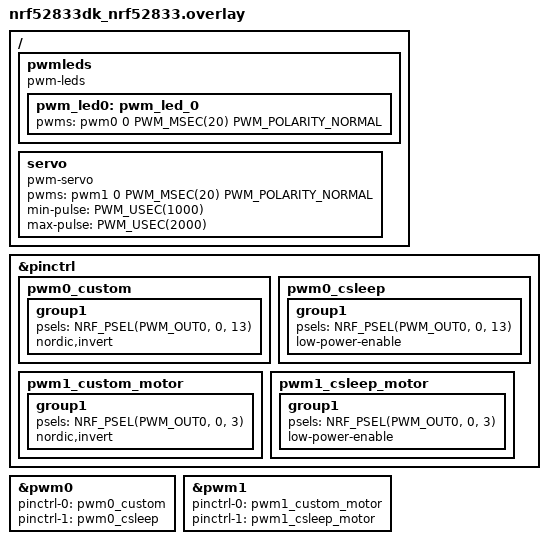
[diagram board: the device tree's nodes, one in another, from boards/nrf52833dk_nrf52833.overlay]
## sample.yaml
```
sample:
  description: nRF Connect SDK Intermediate Course by Nordic Developer Academy (https://academy.nordicsemi.com/)
  name: nRF Connect SDK Intermediate Course (Lesson 6 - Exercise 2 Solution)
```

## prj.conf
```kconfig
# Step 1 - Enable nrfx SAADC driver #
CONFIG_NRFX_SAADC=y
```

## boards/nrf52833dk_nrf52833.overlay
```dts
// To get started, press Ctrl+Space to bring up the completion menu and view the available nodes.

// You can also use the buttons in the sidebar to perform actions on nodes.
// Actions currently available include:

// * Enabling / disabling the node
// * Adding the bus to a bus
// * Removing the node
// * Connecting ADC channels

// For more help, browse the DeviceTree documentation at https://docs.zephyrproject.org/latest/guides/dts/index.html
// You can also visit the nRF DeviceTree extension documentation at https://nrfconnect.github.io/vscode-nrf-connect/devicetree/nrfdevicetree.html



/* STEP 1.4 - Define pwm0_custom and pwm0_sleep */
&pinctrl {
    pwm0_custom: pwm0_custom {
        group1 {
            psels = <NRF_PSEL(PWM_OUT0, 0, 13)>;
            nordic,invert;
        };
    };

    pwm0_csleep: pwm0_csleep {
        group1 {
            psels = <NRF_PSEL(PWM_OUT0, 0, 13)>;
            low-power-enable;
        };
    };
};
/* STEP 1.3 - Add the pwm0 instance */
&pwm0 {
    status = "okay";
    pinctrl-0 = <&pwm0_custom>;
    pinctrl-1 = <&pwm0_csleep>;
    pinctrl-names = "default", "sleep";
};

/{
/* STEP 1.2 -  Add a pwm_led instance and change the polarity */
    pwmleds {
        compatible = "pwm-leds";
        pwm_led0: pwm_led_0 {
            pwms = <&pwm0 0 PWM_MSEC(20) PWM_POLARITY_NORMAL>;
        };
    };
};



/* STEP 5.6 Select what GPIO pwm1 should drive */
&pinctrl {
    pwm1_custom_motor: pwm1_custom_motor {
        group1 {
            psels = <NRF_PSEL(PWM_OUT0, 0, 3)>;
            nordic,invert;
        };
    };

    pwm1_csleep_motor: pwm1_csleep_motor {
        group1 {
            psels = <NRF_PSEL(PWM_OUT0, 0, 3)>;
            low-power-enable;
        };
    };
};

&pwm1 {
    status = "okay";
    pinctrl-0 = <&pwm1_custom_motor>;
    pinctrl-1 = <&pwm1_csleep_motor>;
    pinctrl-names = "default", "sleep";
};

/* STEP 5.5 - Add the servo device  */
/ {
    servo: servo {
        compatible = "pwm-servo";
        pwms = <&pwm1 0 PWM_MSEC(20) PWM_POLARITY_NORMAL>;
        min-pulse = <PWM_USEC(1000)>;
        max-pulse = <PWM_USEC(2000)>;
    };
};
```

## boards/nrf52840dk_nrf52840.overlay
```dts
// To get started, press Ctrl+Space to bring up the completion menu and view the available nodes.

// You can also use the buttons in the sidebar to perform actions on nodes.
// Actions currently available include:

// * Enabling / disabling the node
// * Adding the bus to a bus
// * Removing the node
// * Connecting ADC channels

// For more help, browse the DeviceTree documentation at https://docs.zephyrproject.org/latest/guides/dts/index.html
// You can also visit the nRF DeviceTree extension documentation at https://nrfconnect.github.io/vscode-nrf-connect/devicetree/nrfdevicetree.html



/* STEP 1.4 - Define pwm0_custom and pwm0_sleep */
&pinctrl {
    pwm0_custom: pwm0_custom {
        group1 {
            psels = <NRF_PSEL(PWM_OUT0, 0, 10)>;
            nordic,invert;
        };
    };

    pwm0_csleep: pwm0_csleep {
        group1 {
            psels = <NRF_PSEL(PWM_OUT0, 0, 10)>;
            low-power-enable;
        };
    };
};
/* STEP 1.3 - Add the pwm0 instance */
&pwm0 {
    status = "okay";
    pinctrl-0 = <&pwm0_custom>;
    pinctrl-1 = <&pwm0_csleep>;
    pinctrl-names = "default", "sleep";
};

/{
/* STEP 1.2 -  Add a pwm_led instance and change the polarity */
    pwmleds {
        compatible = "pwm-leds";
        pwm_led0: pwm_led_0 {
            pwms = <&pwm0 0 PWM_MSEC(20) PWM_POLARITY_NORMAL>;
        };
    };
};


/* STEP 5.6 Select what GPIO pwm1 should drive */
&pinctrl {
    pwm1_custom_motor: pwm1_custom_motor {
        group1 {
            psels = <NRF_PSEL(PWM_OUT0, 0, 3)>;
            nordic,invert;
        };
    };

    pwm1_csleep_motor: pwm1_csleep_motor {
        group1 {
            psels = <NRF_PSEL(PWM_OUT0, 0, 3)>;
            low-power-enable;
        };
    };
};

&pwm1 {
    status = "okay";
    pinctrl-0 = <&pwm1_custom_motor>;
    pinctrl-1 = <&pwm1_csleep_motor>;
    pinctrl-names = "default", "sleep";
};

/* STEP 5.5 - Add the servo device  */
/ {
    servo: servo {
        compatible = "pwm-servo";
        pwms = <&pwm1 0 PWM_MSEC(20) PWM_POLARITY_NORMAL>;
        min-pulse = <PWM_USEC(1000)>;
        max-pulse = <PWM_USEC(2000)>;
    };
};
```

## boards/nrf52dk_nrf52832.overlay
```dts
// To get started, press Ctrl+Space to bring up the completion menu and view the available nodes.

// You can also use the buttons in the sidebar to perform actions on nodes.
// Actions currently available include:

// * Enabling / disabling the node
// * Adding the bus to a bus
// * Removing the node
// * Connecting ADC channels

// For more help, browse the DeviceTree documentation at https://docs.zephyrproject.org/latest/guides/dts/index.html
// You can also visit the nRF DeviceTree extension documentation at https://nrfconnect.github.io/vscode-nrf-connect/devicetree/nrfdevicetree.html



/* STEP 1.4 - Define pwm0_custom and pwm0_sleep */
&pinctrl {
    pwm0_custom: pwm0_custom {
        group1 {
            psels = <NRF_PSEL(PWM_OUT0, 0, 17)>;
            nordic,invert;
        };
    };

    pwm0_csleep: pwm0_csleep {
        group1 {
            psels = <NRF_PSEL(PWM_OUT0, 0, 17)>;
            low-power-enable;
        };
    };
};
/* STEP 1.3 - Add the pwm0 instance */
&pwm0 {
    status = "okay";
    pinctrl-0 = <&pwm0_custom>;
    pinctrl-1 = <&pwm0_csleep>;
    pinctrl-names = "default", "sleep";
};

/{
/* STEP 1.2 -  Add a pwm_led instance and change the polarity */
    pwmleds {
        compatible = "pwm-leds";
        pwm_led0: pwm_led_0 {
            pwms = <&pwm0 0 PWM_MSEC(20) PWM_POLARITY_NORMAL>;
        };
    };
};



/* STEP 5.6 Select what GPIO pwm1 should drive */
&pinctrl {
    pwm1_custom_motor: pwm1_custom_motor {
        group1 {
            psels = <NRF_PSEL(PWM_OUT0, 0, 3)>;
            nordic,invert;
        };
    };

    pwm1_csleep_motor: pwm1_csleep_motor {
        group1 {
            psels = <NRF_PSEL(PWM_OUT0, 0, 3)>;
            low-power-enable;
        };
    };
};

&pwm1 {
    status = "okay";
    pinctrl-0 = <&pwm1_custom_motor>;
    pinctrl-1 = <&pwm1_csleep_motor>;
    pinctrl-names = "default", "sleep";
};

/* STEP 5.5 - Add the servo device  */
/ {
    servo: servo {
        compatible = "pwm-servo";
        pwms = <&pwm1 0 PWM_MSEC(20) PWM_POLARITY_NORMAL>;
        min-pulse = <PWM_USEC(1000)>;
        max-pulse = <PWM_USEC(2000)>;
    };
};
```

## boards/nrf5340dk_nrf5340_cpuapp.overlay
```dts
// To get started, press Ctrl+Space to bring up the completion menu and view the available nodes.

// You can also use the buttons in the sidebar to perform actions on nodes.
// Actions currently available include:

// * Enabling / disabling the node
// * Adding the bus to a bus
// * Removing the node
// * Connecting ADC channels

// For more help, browse the DeviceTree documentation at https://docs.zephyrproject.org/latest/guides/dts/index.html
// You can also visit the nRF DeviceTree extension documentation at https://nrfconnect.github.io/vscode-nrf-connect/devicetree/nrfdevicetree.html




/* Step 1.4 - Define pwm0_custom and pwm0_sleep */
&pinctrl {
    pwm0_custom: pwm0_custom {
        group1 {
            psels = <NRF_PSEL(PWM_OUT0, 0, 3)>;
            nordic,invert;
        };
    };

    pwm0_csleep: pwm0_csleep {
        group1 {
            psels = <NRF_PSEL(PWM_OUT0, 0, 3)>;
            low-power-enable;
        };
    };
};
/* Step 1.3 - Add the pwm0 instance */
&pwm0 {
    status = "okay";
    pinctrl-0 = <&pwm0_custom>;
    pinctrl-1 = <&pwm0_csleep>;
    pinctrl-names = "default", "sleep";
};

/{
/* Step 1.2 -  Add a pwm_led instance and change the polarity */
    pwmleds {
        compatible = "pwm-leds";
        pwm_led0: pwm_led_0 {
            pwms = <&pwm0 0 PWM_MSEC(20) PWM_POLARITY_NORMAL>;
        };
    };
};
```

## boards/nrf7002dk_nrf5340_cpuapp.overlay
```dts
// To get started, press Ctrl+Space to bring up the completion menu and view the available nodes.

// You can also use the buttons in the sidebar to perform actions on nodes.
// Actions currently available include:

// * Enabling / disabling the node
// * Adding the bus to a bus
// * Removing the node
// * Connecting ADC channels

// For more help, browse the DeviceTree documentation at https://docs.zephyrproject.org/latest/guides/dts/index.html
// You can also visit the nRF DeviceTree extension documentation at https://nrfconnect.github.io/vscode-nrf-connect/devicetree/nrfdevicetree.html



/* STEP 1.4 - Define pwm0_custom and pwm0_sleep */
&pinctrl {
    pwm0_custom: pwm0_custom {
        group1 {
            psels = <NRF_PSEL(PWM_OUT0, 1, 6)>;
            nordic,invert;
        };
    };

    pwm0_csleep: pwm0_csleep {
        group1 {
            psels = <NRF_PSEL(PWM_OUT0, 1, 6)>;
            low-power-enable;
        };
    };
};
/* STEP 1.3 - Add the pwm0 instance */
&pwm0 {
    status = "okay";
    pinctrl-0 = <&pwm0_custom>;
    pinctrl-1 = <&pwm0_csleep>;
    pinctrl-names = "default", "sleep";
};

/{
/* STEP 1.2 -  Add a pwm_led instance and change the polarity */
    pwmleds {
        compatible = "pwm-leds";
        pwm_led0: pwm_led_0 {
            pwms = <&pwm0 0 PWM_MSEC(20) PWM_POLARITY_NORMAL>;
        };
    };
};


/* STEP 5.6 Select what GPIO pwm1 should drive */
&pinctrl {
    pwm1_custom_motor: pwm1_custom_motor {
        group1 {
            psels = <NRF_PSEL(PWM_OUT0, 1, 7)>;
            nordic,invert;
        };
    };

    pwm1_csleep_motor: pwm1_csleep_motor {
        group1 {
            psels = <NRF_PSEL(PWM_OUT0, 1, 7)>;
            low-power-enable;
        };
    };
};

&pwm1 {
    status = "okay";
    pinctrl-0 = <&pwm1_custom_motor>;
    pinctrl-1 = <&pwm1_csleep_motor>;
    pinctrl-names = "default", "sleep";
};

/* STEP 5.5 - Add the servo device 
For the nRF7002DK we will be using LED2 as our "servo motor" due to voltage supply limitations. The DK can only
supply 1.8v while the motor requires a higher voltage. Since the hands on exercise follows the same configurations for all DKs, i.e that 
pwm1 simulates the parameters for the motor, you will only see LED 2 light dimly. You will also have to reconfigure the buttons so that button 1 and 2 toggles the pwm 
connected to pwm0 instead of pwm1 if you wish to see a meaningful change in LED blinking frequency.
*/
/ {
    servo: servo {
        compatible = "pwm-servo";
        pwms = <&pwm1 0 PWM_MSEC(20) PWM_POLARITY_NORMAL>;
        min-pulse = <PWM_USEC(1000)>;
        max-pulse = <PWM_USEC(2000)>;
    };
};
```

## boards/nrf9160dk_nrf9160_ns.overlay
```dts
// To get started, press Ctrl+Space to bring up the completion menu and view the available nodes.

// You can also use the buttons in the sidebar to perform actions on nodes.
// Actions currently available include:

// * Enabling / disabling the node
// * Adding the bus to a bus
// * Removing the node
// * Connecting ADC channels

// For more help, browse the DeviceTree documentation at https://docs.zephyrproject.org/latest/guides/dts/index.html
// You can also visit the nRF DeviceTree extension documentation at https://nrfconnect.github.io/vscode-nrf-connect/devicetree/nrfdevicetree.html

// To get started, press Ctrl+Space to bring up the completion menu and view the available nodes.

// You can also use the buttons in the sidebar to perform actions on nodes.
// Actions currently available include:

// * Enabling / disabling the node
// * Adding the bus to a bus
// * Removing the node
// * Connecting ADC channels

// For more help, browse the DeviceTree documentation at https://docs.zephyrproject.org/latest/guides/dts/index.html
// You can also visit the nRF DeviceTree extension documentation at https://nrfconnect.github.io/vscode-nrf-connect/devicetree/nrfdevicetree.html



/* STEP 1.4 - Define pwm0_custom and pwm0_sleep */
&pinctrl {
    pwm0_custom: pwm0_custom {
        group1 {
            psels = <NRF_PSEL(PWM_OUT0, 0, 2)>;
            nordic,invert;
        };
    };

    pwm0_csleep: pwm0_csleep {
        group1 {
            psels = <NRF_PSEL(PWM_OUT0, 0, 2)>;
            low-power-enable;
        };
    };
};
/* STEP 1.3 - Add the pwm0 instance */
&pwm0 {
    status = "okay";
    pinctrl-0 = <&pwm0_custom>;
    pinctrl-1 = <&pwm0_csleep>;
    pinctrl-names = "default", "sleep";
};

/{
/* STEP 1.2 -  Add a pwm_led instance and change the polarity */
    pwmleds {
        compatible = "pwm-leds";
        pwm_led0: pwm_led_0 {
            pwms = <&pwm0 0 PWM_MSEC(20) PWM_POLARITY_NORMAL>;
        };
    };
};


/* STEP 5.6 Select what GPIO pwm1 should drive */
&pinctrl {
    pwm1_custom_motor: pwm1_custom_motor {
        group1 {
            psels = <NRF_PSEL(PWM_OUT0, 0, 10)>;
            nordic,invert;
        };
    };

    pwm1_csleep_motor: pwm1_csleep_motor {
        group1 {
            psels = <NRF_PSEL(PWM_OUT0, 0, 10)>;
            low-power-enable;
        };
    };
};

&pwm1 {
    status = "okay";
    pinctrl-0 = <&pwm1_custom_motor>;
    pinctrl-1 = <&pwm1_csleep_motor>;
    pinctrl-names = "default", "sleep";
};

/* STEP 5.5 - Add the servo device  */
/ {
    servo: servo {
        compatible = "pwm-servo";
        pwms = <&pwm1 0 PWM_MSEC(20) PWM_POLARITY_NORMAL>;
        min-pulse = <PWM_USEC(1000)>;
        max-pulse = <PWM_USEC(2000)>;
    };
};
```

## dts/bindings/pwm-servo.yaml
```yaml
# Copyright (c) 2022 Nordic Semiconductor ASA
# SPDX-License-Identifier: Apache-2.0

description: PWM-driven servo motor.

compatible: "pwm-servo"

include: base.yaml

properties:
  pwms:
    required: true
    type: phandle-array
    description: PWM specifier driving the servo motor.

  min-pulse:
    required: true
    type: int
    description: Minimum pulse width (nanoseconds).

  max-pulse:
    required: true
    type: int
    description: Maximum pulse width (nanoseconds).
  
```

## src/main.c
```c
/*
 * Copyright (c) 2024 Nordic Semiconductor ASA
 *
 * SPDX-License-Identifier: LicenseRef-Nordic-5-Clause
 */

#include <zephyr/kernel.h>
#include <zephyr/sys/printk.h>

/* STEP 2 - Include header for nrfx SAADC driver */
#include <nrfx_saadc.h>

/* STEP 3.1 - Declare the struct to hold the configuration for the SAADC channel used to sample the battery voltage */
static nrfx_saadc_channel_t channel = NRFX_SAADC_DEFAULT_CHANNEL_SE(NRF_SAADC_INPUT_AIN0, 0);

/* STEP 3.2 - Declare the buffer to hold the SAAD sample value */
static int16_t sample;

/* STEP 4.1 - Define the battery sample interval */
#define BATTERY_SAMPLE_INTERVAL_MS 2000

/* STEP 4.3 - Add forward declaration of timer callback handler */
static void battery_sample_timer_handler(struct k_timer *timer);

/* STEP 4.2 - Define the battery sample timer instance */
K_TIMER_DEFINE(battery_sample_timer, battery_sample_timer_handler, NULL);

/* STEP 7.1 - Implement timer callback handler function */
void battery_sample_timer_handler(struct k_timer *timer)
{

        /* STEP 7.2 - Trigger the sampling */
        nrfx_err_t err = nrfx_saadc_mode_trigger();
        if (err != NRFX_SUCCESS) {
                printk("nrfx_saadc_mode_trigger error: %08x", err);
                return;
        }

        /* STEP 7.3 - Calculate and print voltage */
        int battery_voltage = ((600*6) * sample) / ((1<<12));

        printk("SAADC sample: %d\n", sample);
        printk("Battery Voltage: %d mV\n", battery_voltage);

}

static void configure_saadc(void)
{
        /* STEP 5.1 - Connect ADC interrupt to nrfx interrupt handler */
        IRQ_CONNECT(DT_IRQN(DT_NODELABEL(adc)),
		    DT_IRQ(DT_NODELABEL(adc), priority),
		    nrfx_isr, nrfx_saadc_irq_handler, 0);
        
        /* STEP 5.2 - Initialize the nrfx_SAADC driver */
        nrfx_err_t err = nrfx_saadc_init(DT_IRQ(DT_NODELABEL(adc), priority));
        if (err != NRFX_SUCCESS) 
        {
                printk("nrfx_saadc_mode_trigger error: %08x", err);
                return;
        }

        /* STEP 5.3 - Configure the SAADC channel */
        channel.channel_config.gain = NRF_SAADC_GAIN1_6;
        err = nrfx_saadc_channels_config(&channel, 1);
        if (err != NRFX_SUCCESS) 
        {
		printk("nrfx_saadc_channels_config error: %08x", err);
	        return;
	}

        /* STEP 5.4 - Configure nrfx_SAADC driver in simple and blocking mode */
        err = nrfx_saadc_simple_mode_set(BIT(0),
                                         NRF_SAADC_RESOLUTION_12BIT,
                                         NRF_SAADC_OVERSAMPLE_DISABLED,
                                         NULL);
        if (err != NRFX_SUCCESS) {
                printk("nrfx_saadc_simple_mode_set error: %08x", err);
                return;
        }
        
        /* STEP 5.5 - Set buffer where sample will be stored */
        err = nrfx_saadc_buffer_set(&sample, 1);
        if (err != NRFX_SUCCESS) {
                printk("nrfx_saadc_buffer_set error: %08x", err);
                return;
        }

        /* STEP 6 - Start periodic timer for battery sampling */
	k_timer_start(&battery_sample_timer, K_NO_WAIT, K_MSEC(BATTERY_SAMPLE_INTERVAL_MS));

}

int main(void)
{
        configure_saadc();

        k_sleep(K_FOREVER);
        return 0;
}
```
